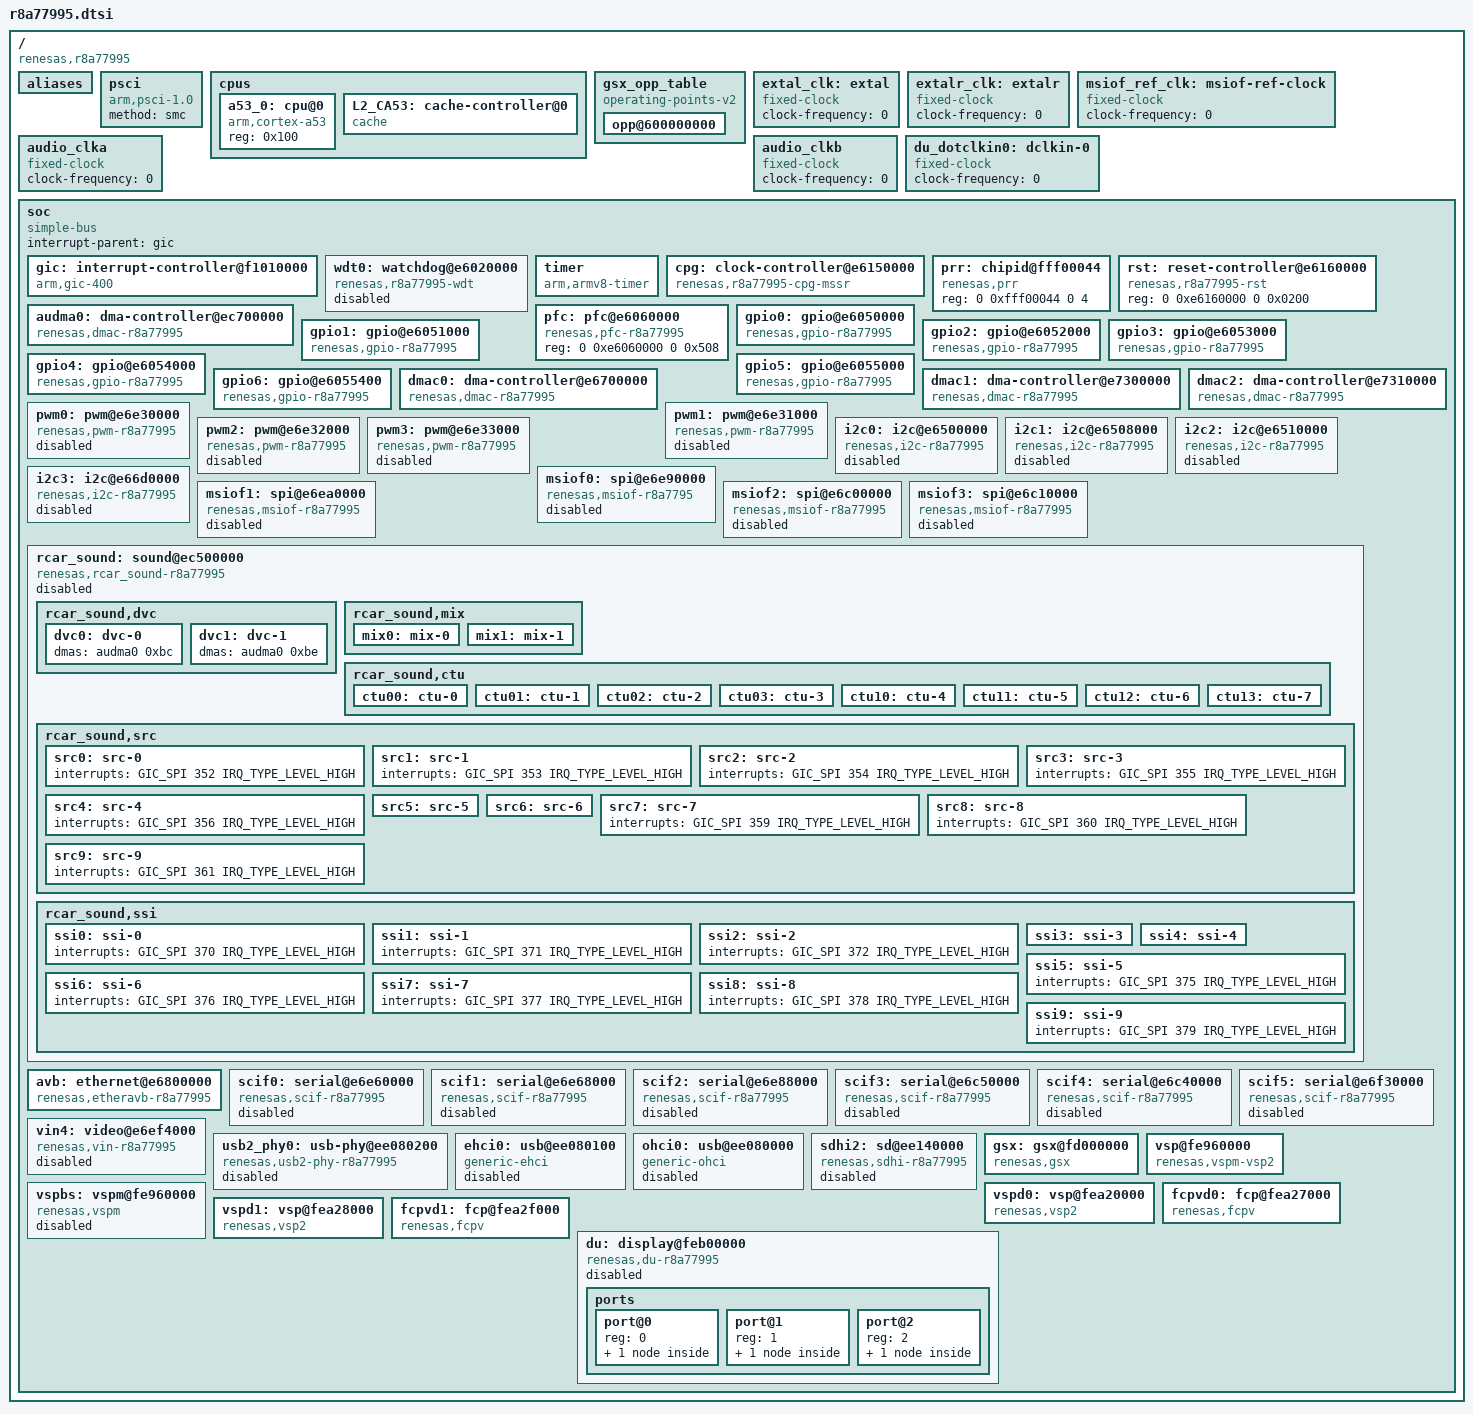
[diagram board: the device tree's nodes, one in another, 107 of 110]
/*
 * Device Tree Source for the r8a77995 SoC
 *
 * Copyright (C) 2017 Renesas Electronics Corp.
 *
 * This file is licensed under the terms of the GNU General Public License
 * version 2.  This program is licensed "as is" without any warranty of any
 * kind, whether express or implied.
 */

#include <dt-bindings/clock/r8a77995-cpg-mssr.h>
#include <dt-bindings/interrupt-controller/arm-gic.h>

/ {
	compatible = "renesas,r8a77995";
	#address-cells = <2>;
	#size-cells = <2>;

	aliases {
		i2c0 = &i2c0;
		i2c1 = &i2c1;
		i2c2 = &i2c2;
		i2c3 = &i2c3;
		spi1 = &msiof0;
		spi2 = &msiof1;
		spi3 = &msiof2;
		spi4 = &msiof3;
		vin4 = &vin4;
	};

	psci {
		compatible = "arm,psci-1.0";
		method = "smc";
	};

	cpus {
		#address-cells = <1>;
		#size-cells = <0>;

		a53_0: cpu@0 {
			compatible = "arm,cortex-a53", "arm,armv8";
			reg = <0x100>;
			device_type = "cpu";
		};

		L2_CA53: cache-controller@0 {
			compatible = "cache";
			reg = <0x100>;
			cache-unified;
			cache-level = <2>;
		};
	};

	gsx_opp_table: gsx_opp_table {
		compatible = "operating-points-v2";

		opp@600000000 {
			opp-hz = /bits/ 64 <600000000>;
			opp-microvolt = <1030000>;
		};
	};

	extal_clk: extal {
		compatible = "fixed-clock";
		#clock-cells = <0>;
		/* This value must be overridden by the board */
		clock-frequency = <0>;
	};

	extalr_clk: extalr {
		compatible = "fixed-clock";
		#clock-cells = <0>;
		/* This value must be overridden by the board */
		clock-frequency = <0>;
	};

	/* MSIOF reference clock - to be overridden by boards that provide it */
	msiof_ref_clk: msiof-ref-clock {
		compatible = "fixed-clock";
		#clock-cells = <0>;
		clock-frequency = <0>;
	};

	/*
	 * The external audio clocks are configured as 0 Hz fixed frequency
	 * clocks by default.
	 * Boards that provide audio clocks should override them.
	 */
	audio_clka: audio_clka {
		compatible = "fixed-clock";
		#clock-cells = <0>;
		clock-frequency = <0>;
	};

	audio_clkb: audio_clkb {
		compatible = "fixed-clock";
		#clock-cells = <0>;
		clock-frequency = <0>;
	};

	/* DU input dot clock - to be overridden by boards that provide it */
	du_dotclkin0: dclkin-0 {
		compatible = "fixed-clock";
		#clock-cells = <0>;
		clock-frequency = <0>;
	};

	soc {
		compatible = "simple-bus";
		interrupt-parent = <&gic>;

		#address-cells = <2>;
		#size-cells = <2>;
		ranges;

		gic: interrupt-controller@f1010000 {
			compatible = "arm,gic-400";
			#interrupt-cells = <3>;
			#address-cells = <0>;
			interrupt-controller;
			reg = <0x0 0xf1010000 0 0x1000>,
			      <0x0 0xf1020000 0 0x20000>,
			      <0x0 0xf1040000 0 0x20000>,
			      <0x0 0xf1060000 0 0x20000>;
			interrupts = <GIC_PPI 9
					(GIC_CPU_MASK_SIMPLE(1) |
					 IRQ_TYPE_LEVEL_HIGH)>;
		};

		wdt0: watchdog@e6020000 {
			compatible = "renesas,r8a77995-wdt",
				     "renesas,rcar-gen3-wdt";
			reg = <0 0xe6020000 0 0x0c>;
			clocks = <&cpg CPG_MOD 402>;
			power-domains = <&cpg>;
			status = "disabled";
		};

		timer {
			compatible = "arm,armv8-timer";
			interrupts = <GIC_PPI 13
					(GIC_CPU_MASK_SIMPLE(1) |
					 IRQ_TYPE_LEVEL_LOW)>,
				     <GIC_PPI 14
					(GIC_CPU_MASK_SIMPLE(1) |
					 IRQ_TYPE_LEVEL_LOW)>,
				     <GIC_PPI 11
					(GIC_CPU_MASK_SIMPLE(1) |
					 IRQ_TYPE_LEVEL_LOW)>,
				     <GIC_PPI 10
					(GIC_CPU_MASK_SIMPLE(1) |
					 IRQ_TYPE_LEVEL_LOW)>;
		};

		cpg: clock-controller@e6150000 {
			compatible = "renesas,r8a77995-cpg-mssr";
			reg = <0 0xe6150000 0 0x1000>;
			clocks = <&extal_clk>, <&extalr_clk>;
			clock-names = "extal", "extalr";
			#clock-cells = <2>;
			#power-domain-cells = <0>;
		};

		prr: chipid@fff00044 {
			compatible = "renesas,prr";
			reg = <0 0xfff00044 0 4>;
		};

		rst: reset-controller@e6160000 {
			compatible = "renesas,r8a77995-rst";
			reg = <0 0xe6160000 0 0x0200>;
		};

		audma0: dma-controller@ec700000 {
			compatible = "renesas,dmac-r8a77995",
				     "renesas,rcar-dmac";
			reg = <0 0xec700000 0 0x10000>;
			interrupts = <GIC_SPI 350 IRQ_TYPE_LEVEL_HIGH
				      GIC_SPI 320 IRQ_TYPE_LEVEL_HIGH
				      GIC_SPI 321 IRQ_TYPE_LEVEL_HIGH
				      GIC_SPI 322 IRQ_TYPE_LEVEL_HIGH
				      GIC_SPI 323 IRQ_TYPE_LEVEL_HIGH
				      GIC_SPI 324 IRQ_TYPE_LEVEL_HIGH
				      GIC_SPI 325 IRQ_TYPE_LEVEL_HIGH
				      GIC_SPI 326 IRQ_TYPE_LEVEL_HIGH
				      GIC_SPI 327 IRQ_TYPE_LEVEL_HIGH
				      GIC_SPI 328 IRQ_TYPE_LEVEL_HIGH
				      GIC_SPI 329 IRQ_TYPE_LEVEL_HIGH
				      GIC_SPI 330 IRQ_TYPE_LEVEL_HIGH
				      GIC_SPI 331 IRQ_TYPE_LEVEL_HIGH
				      GIC_SPI 332 IRQ_TYPE_LEVEL_HIGH
				      GIC_SPI 333 IRQ_TYPE_LEVEL_HIGH
				      GIC_SPI 334 IRQ_TYPE_LEVEL_HIGH
				      GIC_SPI 335 IRQ_TYPE_LEVEL_HIGH>;
			interrupt-names = "error",
					"ch0", "ch1", "ch2", "ch3",
					"ch4", "ch5", "ch6", "ch7",
					"ch8", "ch9", "ch10", "ch11",
					"ch12", "ch13", "ch14", "ch15";
			clocks = <&cpg CPG_MOD 502>;
			clock-names = "fck";
			power-domains = <&cpg>;
			#dma-cells = <1>;
			dma-channels = <16>;
		};

		pfc: pfc@e6060000 {
			compatible = "renesas,pfc-r8a77995";
			reg = <0 0xe6060000 0 0x508>;
		};

		gpio0: gpio@e6050000 {
			compatible = "renesas,gpio-r8a77995",
				     "renesas,gpio-rcar";
			reg = <0 0xe6050000 0 0x50>;
			interrupts = <GIC_SPI 4 IRQ_TYPE_LEVEL_HIGH>;
			#gpio-cells = <2>;
			gpio-controller;
			gpio-ranges = <&pfc 0 0 9>;
			#interrupt-cells = <2>;
			interrupt-controller;
			clocks = <&cpg CPG_MOD 912>;
			power-domains = <&cpg>;
		};

		gpio1: gpio@e6051000 {
			compatible = "renesas,gpio-r8a77995",
				     "renesas,gpio-rcar";
			reg = <0 0xe6051000 0 0x50>;
			interrupts = <GIC_SPI 5 IRQ_TYPE_LEVEL_HIGH>;
			#gpio-cells = <2>;
			gpio-controller;
			gpio-ranges = <&pfc 0 32 32>;
			#interrupt-cells = <2>;
			interrupt-controller;
			clocks = <&cpg CPG_MOD 911>;
			power-domains = <&cpg>;
		};

		gpio2: gpio@e6052000 {
			compatible = "renesas,gpio-r8a77995",
				     "renesas,gpio-rcar";
			reg = <0 0xe6052000 0 0x50>;
			interrupts = <GIC_SPI 6 IRQ_TYPE_LEVEL_HIGH>;
			#gpio-cells = <2>;
			gpio-controller;
			gpio-ranges = <&pfc 0 64 32>;
			#interrupt-cells = <2>;
			interrupt-controller;
			clocks = <&cpg CPG_MOD 910>;
			power-domains = <&cpg>;
		};

		gpio3: gpio@e6053000 {
			compatible = "renesas,gpio-r8a77995",
				     "renesas,gpio-rcar";
			reg = <0 0xe6053000 0 0x50>;
			interrupts = <GIC_SPI 7 IRQ_TYPE_LEVEL_HIGH>;
			#gpio-cells = <2>;
			gpio-controller;
			gpio-ranges = <&pfc 0 96 10>;
			#interrupt-cells = <2>;
			interrupt-controller;
			clocks = <&cpg CPG_MOD 909>;
			power-domains = <&cpg>;
		};

		gpio4: gpio@e6054000 {
			compatible = "renesas,gpio-r8a77995",
				     "renesas,gpio-rcar";
			reg = <0 0xe6054000 0 0x50>;
			interrupts = <GIC_SPI 8 IRQ_TYPE_LEVEL_HIGH>;
			#gpio-cells = <2>;
			gpio-controller;
			gpio-ranges = <&pfc 0 128 32>;
			#interrupt-cells = <2>;
			interrupt-controller;
			clocks = <&cpg CPG_MOD 908>;
			power-domains = <&cpg>;
		};

		gpio5: gpio@e6055000 {
			compatible = "renesas,gpio-r8a77995",
				     "renesas,gpio-rcar";
			reg = <0 0xe6055000 0 0x50>;
			interrupts = <GIC_SPI 9 IRQ_TYPE_LEVEL_HIGH>;
			#gpio-cells = <2>;
			gpio-controller;
			gpio-ranges = <&pfc 0 160 21>;
			#interrupt-cells = <2>;
			interrupt-controller;
			clocks = <&cpg CPG_MOD 907>;
			power-domains = <&cpg>;
		};

		gpio6: gpio@e6055400 {
			compatible = "renesas,gpio-r8a77995",
				     "renesas,gpio-rcar";
			reg = <0 0xe6055400 0 0x50>;
			interrupts = <GIC_SPI 10 IRQ_TYPE_LEVEL_HIGH>;
			#gpio-cells = <2>;
			gpio-controller;
			gpio-ranges = <&pfc 0 192 14>;
			#interrupt-cells = <2>;
			interrupt-controller;
			clocks = <&cpg CPG_MOD 906>;
			power-domains = <&cpg>;
		};

		dmac0: dma-controller@e6700000 {
			compatible = "renesas,dmac-r8a77995",
				     "renesas,rcar-dmac";
			reg = <0 0xe6700000 0 0x10000>;
			interrupts = <GIC_SPI 199 IRQ_TYPE_LEVEL_HIGH
				      GIC_SPI 200 IRQ_TYPE_LEVEL_HIGH
				      GIC_SPI 201 IRQ_TYPE_LEVEL_HIGH
				      GIC_SPI 202 IRQ_TYPE_LEVEL_HIGH
				      GIC_SPI 203 IRQ_TYPE_LEVEL_HIGH
				      GIC_SPI 204 IRQ_TYPE_LEVEL_HIGH
				      GIC_SPI 205 IRQ_TYPE_LEVEL_HIGH
				      GIC_SPI 206 IRQ_TYPE_LEVEL_HIGH
				      GIC_SPI 207 IRQ_TYPE_LEVEL_HIGH>;
			interrupt-names = "error",
					"ch0", "ch1", "ch2", "ch3",
					"ch4", "ch5", "ch6", "ch7";
			clocks = <&cpg CPG_MOD 219>;
			clock-names = "fck";
			power-domains = <&cpg>;
			#dma-cells = <1>;
			dma-channels = <8>;
		};

		dmac1: dma-controller@e7300000 {
			compatible = "renesas,dmac-r8a77995",
				     "renesas,rcar-dmac";
			reg = <0 0xe7300000 0 0x10000>;
			interrupts = <GIC_SPI 220 IRQ_TYPE_LEVEL_HIGH
				      GIC_SPI 216 IRQ_TYPE_LEVEL_HIGH
				      GIC_SPI 217 IRQ_TYPE_LEVEL_HIGH
				      GIC_SPI 218 IRQ_TYPE_LEVEL_HIGH
				      GIC_SPI 219 IRQ_TYPE_LEVEL_HIGH
				      GIC_SPI 308 IRQ_TYPE_LEVEL_HIGH
				      GIC_SPI 309 IRQ_TYPE_LEVEL_HIGH
				      GIC_SPI 310 IRQ_TYPE_LEVEL_HIGH
				      GIC_SPI 311 IRQ_TYPE_LEVEL_HIGH>;
			interrupt-names = "error",
					"ch0", "ch1", "ch2", "ch3",
					"ch4", "ch5", "ch6", "ch7";
			clocks = <&cpg CPG_MOD 218>;
			clock-names = "fck";
			power-domains = <&cpg>;
			#dma-cells = <1>;
			dma-channels = <8>;
		};

		dmac2: dma-controller@e7310000 {
			compatible = "renesas,dmac-r8a77995",
				     "renesas,rcar-dmac";
			reg = <0 0xe7310000 0 0x10000>;
			interrupts = <GIC_SPI 416 IRQ_TYPE_LEVEL_HIGH
				      GIC_SPI 417 IRQ_TYPE_LEVEL_HIGH
				      GIC_SPI 418 IRQ_TYPE_LEVEL_HIGH
				      GIC_SPI 419 IRQ_TYPE_LEVEL_HIGH
				      GIC_SPI 420 IRQ_TYPE_LEVEL_HIGH
				      GIC_SPI 421 IRQ_TYPE_LEVEL_HIGH
				      GIC_SPI 422 IRQ_TYPE_LEVEL_HIGH
				      GIC_SPI 423 IRQ_TYPE_LEVEL_HIGH
				      GIC_SPI 424 IRQ_TYPE_LEVEL_HIGH>;
			interrupt-names = "error",
					"ch0", "ch1", "ch2", "ch3",
					"ch4", "ch5", "ch6", "ch7";
			clocks = <&cpg CPG_MOD 217>;
			clock-names = "fck";
			power-domains = <&cpg>;
			#dma-cells = <1>;
			dma-channels = <8>;
		};

		pwm0: pwm@e6e30000 {
			compatible = "renesas,pwm-r8a77995", "renesas,pwm-rcar";
			reg = <0 0xe6e30000 0 0x10>;
			#pwm-cells = <2>;
			clocks = <&cpg CPG_MOD 523>;
			power-domains = <&cpg>;
			status = "disabled";
		};

		pwm1: pwm@e6e31000 {
			compatible = "renesas,pwm-r8a77995", "renesas,pwm-rcar";
			reg = <0 0xe6e31000 0 0x10>;
			#pwm-cells = <2>;
			clocks = <&cpg CPG_MOD 523>;
			power-domains = <&cpg>;
			status = "disabled";
		};

		pwm2: pwm@e6e32000 {
			compatible = "renesas,pwm-r8a77995", "renesas,pwm-rcar";
			reg = <0 0xe6e32000 0 0x10>;
			#pwm-cells = <2>;
			clocks = <&cpg CPG_MOD 523>;
			power-domains = <&cpg>;
			status = "disabled";
		};

		pwm3: pwm@e6e33000 {
			compatible = "renesas,pwm-r8a77995", "renesas,pwm-rcar";
			reg = <0 0xe6e33000 0 0x10>;
			#pwm-cells = <2>;
			clocks = <&cpg CPG_MOD 523>;
			power-domains = <&cpg>;
			status = "disabled";
		};

		i2c0: i2c@e6500000 {
			#address-cells = <1>;
			#size-cells = <0>;
			compatible = "renesas,i2c-r8a77995";
			reg = <0 0xe6500000 0 0x40>;
			interrupts = <GIC_SPI 287 IRQ_TYPE_LEVEL_HIGH>;
			clocks = <&cpg CPG_MOD 931>;
			power-domains = <&cpg>;
			i2c-scl-internal-delay-ns = <110>;
			status = "disabled";
		};

		i2c1: i2c@e6508000 {
			#address-cells = <1>;
			#size-cells = <0>;
			compatible = "renesas,i2c-r8a77995";
			reg = <0 0xe6508000 0 0x40>;
			interrupts = <GIC_SPI 288 IRQ_TYPE_LEVEL_HIGH>;
			clocks = <&cpg CPG_MOD 930>;
			power-domains = <&cpg>;
			i2c-scl-internal-delay-ns = <6>;
			status = "disabled";
		};

		i2c2: i2c@e6510000 {
			#address-cells = <1>;
			#size-cells = <0>;
			compatible = "renesas,i2c-r8a77995";
			reg = <0 0xe6510000 0 0x40>;
			interrupts = <GIC_SPI 286 IRQ_TYPE_LEVEL_HIGH>;
			clocks = <&cpg CPG_MOD 929>;
			power-domains = <&cpg>;
			i2c-scl-internal-delay-ns = <6>;
			status = "disabled";
		};

		i2c3: i2c@e66d0000 {
			#address-cells = <1>;
			#size-cells = <0>;
			compatible = "renesas,i2c-r8a77995";
			reg = <0 0xe66d0000 0 0x40>;
			interrupts = <GIC_SPI 290 IRQ_TYPE_LEVEL_HIGH>;
			clocks = <&cpg CPG_MOD 928>;
			power-domains = <&cpg>;
			i2c-scl-internal-delay-ns = <110>;
			status = "disabled";
		};

		msiof0: spi@e6e90000 {
			#address-cells = <1>;
			#size-cells = <0>;
			compatible = "renesas,msiof-r8a7795";
			reg = <0 0xe6e90000 0 0x64>;
			interrupts = <GIC_SPI 156 IRQ_TYPE_LEVEL_HIGH>;
			clocks = <&cpg CPG_MOD 211>, <&msiof_ref_clk>;
			clock-names = "msiof_clk", "msiof_ref_clk";
			dmas = <&dmac1 0x41>, <&dmac1 0x40>;
			dma-names = "tx", "rx";
			power-domains = <&cpg>;
			status = "disabled";
		};

		msiof1: spi@e6ea0000 {
			#address-cells = <1>;
			#size-cells = <0>;
			compatible = "renesas,msiof-r8a77995";
			reg = <0 0xe6ea0000 0 0x0064>;
			interrupts = <GIC_SPI 157 IRQ_TYPE_LEVEL_HIGH>;
			clocks = <&cpg CPG_MOD 210>, <&msiof_ref_clk>;
			clock-names = "msiof_clk", "msiof_ref_clk";
			dmas = <&dmac1 0x43>, <&dmac1 0x42>;
			dma-names = "tx", "rx";
			power-domains = <&cpg>;
			status = "disabled";
		};

		msiof2: spi@e6c00000 {
			#address-cells = <1>;
			#size-cells = <0>;
			compatible = "renesas,msiof-r8a77995";
			reg = <0 0xe6c00000 0 0x0064>;
			interrupts = <GIC_SPI 158 IRQ_TYPE_LEVEL_HIGH>;
			clocks = <&cpg CPG_MOD 209>, <&msiof_ref_clk>;
			clock-names = "msiof_clk", "msiof_ref_clk";
			dmas = <&dmac0 0x45>, <&dmac0 0x44>;
			dma-names = "tx", "rx";
			power-domains = <&cpg>;
			status = "disabled";
		};

		msiof3: spi@e6c10000 {
			#address-cells = <1>;
			#size-cells = <0>;
			compatible = "renesas,msiof-r8a77995";
			reg = <0 0xe6c10000 0 0x0064>;
			interrupts = <GIC_SPI 159 IRQ_TYPE_LEVEL_HIGH>;
			clocks = <&cpg CPG_MOD 208>, <&msiof_ref_clk>;
			clock-names = "msiof_clk", "msiof_ref_clk";
			dmas = <&dmac0 0x47>, <&dmac0 0x46>;
			dma-names = "tx", "rx";
			power-domains = <&cpg>;
			status = "disabled";
		};

		rcar_sound: sound@ec500000 {
			/*
			 * #sound-dai-cells is required
			 *
			 * Single DAI : #sound-dai-cells = <0>;	<&rcar_sound>;
			 * Multi  DAI : #sound-dai-cells = <1>;	<&rcar_sound N>;
			 */
			/*
			 * #clock-cells is required for audio_clkout0/1/2/3
			 *
			 * clkout	: #clock-cells = <0>;	<&rcar_sound>;
			 * clkout0/1/2/3: #clock-cells = <1>;	<&rcar_sound N>;
			 */
			compatible =  "renesas,rcar_sound-r8a77995",
				      "renesas,rcar_sound-gen3";
			reg =	<0 0xec500000 0 0x1000>, /* SCU */
				<0 0xec5a0000 0 0x100>,  /* ADG */
				<0 0xec540000 0 0x1000>, /* SSIU */
				<0 0xec541000 0 0x280>,  /* SSI */
				<0 0xec740000 0 0x200>;  /* Audio DMAC PP */
			reg-names = "scu", "adg", "ssiu", "ssi", "audmapp";

			clocks = <&cpg CPG_MOD 1005>,
				 <&cpg CPG_MOD 1006>, <&cpg CPG_MOD 1007>,
				 <&cpg CPG_MOD 1008>, <&cpg CPG_MOD 1009>,
				 <&cpg CPG_MOD 1010>, <&cpg CPG_MOD 1011>,
				 <&cpg CPG_MOD 1012>, <&cpg CPG_MOD 1013>,
				 <&cpg CPG_MOD 1014>, <&cpg CPG_MOD 1015>,
				 <&cpg CPG_MOD 1022>, <&cpg CPG_MOD 1023>,
				 <&cpg CPG_MOD 1024>, <&cpg CPG_MOD 1025>,
				 <&cpg CPG_MOD 1026>, <&cpg CPG_MOD 1027>,
				 <&cpg CPG_MOD 1028>, <&cpg CPG_MOD 1029>,
				 <&cpg CPG_MOD 1030>, <&cpg CPG_MOD 1031>,
				 <&cpg CPG_MOD 1020>, <&cpg CPG_MOD 1021>,
				 <&cpg CPG_MOD 1020>, <&cpg CPG_MOD 1021>,
				 <&cpg CPG_MOD 1019>, <&cpg CPG_MOD 1018>,
				 <&audio_clka>, <&audio_clkb>,
				 <&cpg CPG_CORE R8A77995_CLK_ZA2>;

			clock-names = "ssi-all",
				      "ssi.9", "ssi.8", "ssi.7", "ssi.6",
				      "ssi.5", "ssi.4", "ssi.3", "ssi.2",
				      "ssi.1", "ssi.0",
				      "src.9", "src.8", "src.7", "src.6",
				      "src.5", "src.4", "src.3", "src.2",
				      "src.1", "src.0",
				      "mix.1", "mix.0",
				      "ctu.1", "ctu.0",
				      "dvc.0", "dvc.1",
				      "clk_a", "clk_b";
			power-domains = <&cpg>;
			status = "disabled";

			rcar_sound,dvc {
				dvc0: dvc-0 {
					dmas = <&audma0 0xbc>;
					dma-names = "tx";
				};
				dvc1: dvc-1 {
					dmas = <&audma0 0xbe>;
					dma-names = "tx";
				};
			};

			rcar_sound,mix {
				mix0: mix-0 { };
				mix1: mix-1 { };
			};

			rcar_sound,ctu {
				ctu00: ctu-0 { };
				ctu01: ctu-1 { };
				ctu02: ctu-2 { };
				ctu03: ctu-3 { };
				ctu10: ctu-4 { };
				ctu11: ctu-5 { };
				ctu12: ctu-6 { };
				ctu13: ctu-7 { };
			};

			rcar_sound,src {
				src0: src-0 {
					interrupts =
					    <GIC_SPI 352 IRQ_TYPE_LEVEL_HIGH>;
				};
				src1: src-1 {
					interrupts =
					    <GIC_SPI 353 IRQ_TYPE_LEVEL_HIGH>;
				};
				src2: src-2 {
					interrupts =
					    <GIC_SPI 354 IRQ_TYPE_LEVEL_HIGH>;
				};
				src3: src-3 {
					interrupts =
					    <GIC_SPI 355 IRQ_TYPE_LEVEL_HIGH>;
				};
				src4: src-4 {
					interrupts =
					    <GIC_SPI 356 IRQ_TYPE_LEVEL_HIGH>;
				};
				src5: src-5 {
					interrupts =
					    <GIC_SPI 357 IRQ_TYPE_LEVEL_HIGH>;
					dmas = <&audma0 0x8f>, <&audma0 0xb2>;
					dma-names = "rx", "tx";
				};
				src6: src-6 {
					interrupts =
					    <GIC_SPI 358 IRQ_TYPE_LEVEL_HIGH>;
					dmas = <&audma0 0x91>, <&audma0 0xb4>;
					dma-names = "rx", "tx";
				};
				src7: src-7 {
					interrupts =
					    <GIC_SPI 359 IRQ_TYPE_LEVEL_HIGH>;
				};
				src8: src-8 {
					interrupts =
					    <GIC_SPI 360 IRQ_TYPE_LEVEL_HIGH>;
				};
				src9: src-9 {
					interrupts =
					    <GIC_SPI 361 IRQ_TYPE_LEVEL_HIGH>;
				};
			};

			rcar_sound,ssi {
				ssi0: ssi-0 {
					interrupts =
					    <GIC_SPI 370 IRQ_TYPE_LEVEL_HIGH>;
				};
				ssi1: ssi-1 {
					 interrupts =
					     <GIC_SPI 371 IRQ_TYPE_LEVEL_HIGH>;
				};
				ssi2: ssi-2 {
					interrupts =
					    <GIC_SPI 372 IRQ_TYPE_LEVEL_HIGH>;
				};
				ssi3: ssi-3 {
					interrupts =
					    <GIC_SPI 373 IRQ_TYPE_LEVEL_HIGH>;
					dmas = <&audma0 0x07>, <&audma0 0x08>,
					       <&audma0 0x6f>, <&audma0 0x70>;
					dma-names = "rx", "tx", "rxu", "txu";
				};
				ssi4: ssi-4 {
					interrupts =
					    <GIC_SPI 374 IRQ_TYPE_LEVEL_HIGH>;
					dmas = <&audma0 0x09>, <&audma0 0x0a>,
					       <&audma0 0x71>, <&audma0 0x72>;
					dma-names = "rx", "tx", "rxu", "txu";
				};
				ssi5: ssi-5 {
					interrupts =
					    <GIC_SPI 375 IRQ_TYPE_LEVEL_HIGH>;
				};
				ssi6: ssi-6 {
					interrupts =
					    <GIC_SPI 376 IRQ_TYPE_LEVEL_HIGH>;
				};
				ssi7: ssi-7 {
					interrupts =
					    <GIC_SPI 377 IRQ_TYPE_LEVEL_HIGH>;
				};
				ssi8: ssi-8 {
					interrupts =
					    <GIC_SPI 378 IRQ_TYPE_LEVEL_HIGH>;
				};
				ssi9: ssi-9 {
					interrupts =
					    <GIC_SPI 379 IRQ_TYPE_LEVEL_HIGH>;
				};
			};
		};

		avb: ethernet@e6800000 {
			compatible = "renesas,etheravb-r8a77995",
				     "renesas,etheravb-rcar-gen3";
			reg = <0 0xe6800000 0 0x800>, <0 0xe6a00000 0 0x10000>;
			interrupts = <GIC_SPI 39 IRQ_TYPE_LEVEL_HIGH>,
				     <GIC_SPI 40 IRQ_TYPE_LEVEL_HIGH>,
				     <GIC_SPI 41 IRQ_TYPE_LEVEL_HIGH>,
				     <GIC_SPI 42 IRQ_TYPE_LEVEL_HIGH>,
				     <GIC_SPI 43 IRQ_TYPE_LEVEL_HIGH>,
				     <GIC_SPI 44 IRQ_TYPE_LEVEL_HIGH>,
				     <GIC_SPI 45 IRQ_TYPE_LEVEL_HIGH>,
				     <GIC_SPI 46 IRQ_TYPE_LEVEL_HIGH>,
				     <GIC_SPI 47 IRQ_TYPE_LEVEL_HIGH>,
				     <GIC_SPI 48 IRQ_TYPE_LEVEL_HIGH>,
				     <GIC_SPI 49 IRQ_TYPE_LEVEL_HIGH>,
				     <GIC_SPI 50 IRQ_TYPE_LEVEL_HIGH>,
				     <GIC_SPI 51 IRQ_TYPE_LEVEL_HIGH>,
				     <GIC_SPI 52 IRQ_TYPE_LEVEL_HIGH>,
				     <GIC_SPI 53 IRQ_TYPE_LEVEL_HIGH>,
				     <GIC_SPI 54 IRQ_TYPE_LEVEL_HIGH>,
				     <GIC_SPI 55 IRQ_TYPE_LEVEL_HIGH>,
				     <GIC_SPI 56 IRQ_TYPE_LEVEL_HIGH>,
				     <GIC_SPI 57 IRQ_TYPE_LEVEL_HIGH>,
				     <GIC_SPI 58 IRQ_TYPE_LEVEL_HIGH>,
				     <GIC_SPI 59 IRQ_TYPE_LEVEL_HIGH>,
				     <GIC_SPI 60 IRQ_TYPE_LEVEL_HIGH>,
				     <GIC_SPI 61 IRQ_TYPE_LEVEL_HIGH>,
				     <GIC_SPI 62 IRQ_TYPE_LEVEL_HIGH>,
				     <GIC_SPI 63 IRQ_TYPE_LEVEL_HIGH>;
			interrupt-names = "ch0", "ch1", "ch2", "ch3",
					  "ch4", "ch5", "ch6", "ch7",
					  "ch8", "ch9", "ch10", "ch11",
					  "ch12", "ch13", "ch14", "ch15",
					  "ch16", "ch17", "ch18", "ch19",
					  "ch20", "ch21", "ch22", "ch23",
					  "ch24";
			clocks = <&cpg CPG_MOD 812>;
			power-domains = <&cpg>;
			phy-mode = "rgmii-txid";
			#address-cells = <1>;
			#size-cells = <0>;
		};

		scif0: serial@e6e60000 {
			compatible = "renesas,scif-r8a77995",
				     "renesas,rcar-gen3-scif", "renesas,scif";
			reg = <0 0xe6e60000 0 64>;
			interrupts = <GIC_SPI 152 IRQ_TYPE_LEVEL_HIGH>;
			clocks = <&cpg CPG_MOD 207>;
			clock-names = "fck";
			power-domains = <&cpg>;
			status = "disabled";
		};

		scif1: serial@e6e68000 {
			compatible = "renesas,scif-r8a77995",
				     "renesas,rcar-gen3-scif", "renesas,scif";
			reg = <0 0xe6e68000 0 64>;
			interrupts = <GIC_SPI 153 IRQ_TYPE_LEVEL_HIGH>;
			clocks = <&cpg CPG_MOD 206>;
			clock-names = "fck";
			power-domains = <&cpg>;
			status = "disabled";
		};

		scif2: serial@e6e88000 {
			compatible = "renesas,scif-r8a77995",
				     "renesas,rcar-gen3-scif", "renesas,scif";
			reg = <0 0xe6e88000 0 64>;
			interrupts = <GIC_SPI 164 IRQ_TYPE_LEVEL_HIGH>;
			clocks = <&cpg CPG_MOD 310>;
			clock-names = "fck";
			power-domains = <&cpg>;
			status = "disabled";
		};

		scif3: serial@e6c50000 {
			compatible = "renesas,scif-r8a77995",
				     "renesas,rcar-gen3-scif", "renesas,scif";
			reg = <0 0xe6c50000 0 64>;
			interrupts = <GIC_SPI 23 IRQ_TYPE_LEVEL_HIGH>;
			clocks = <&cpg CPG_MOD 204>;
			clock-names = "fck";
			power-domains = <&cpg>;
			status = "disabled";
		};

		scif4: serial@e6c40000 {
			compatible = "renesas,scif-r8a77995",
				     "renesas,rcar-gen3-scif", "renesas,scif";
			reg = <0 0xe6c40000 0 64>;
			interrupts = <GIC_SPI 16 IRQ_TYPE_LEVEL_HIGH>;
			clocks = <&cpg CPG_MOD 203>;
			clock-names = "fck";
			power-domains = <&cpg>;
			status = "disabled";
		};

		scif5: serial@e6f30000 {
			compatible = "renesas,scif-r8a77995",
				     "renesas,rcar-gen3-scif", "renesas,scif";
			reg = <0 0xe6f30000 0 64>;
			interrupts = <GIC_SPI 17 IRQ_TYPE_LEVEL_HIGH>;
			clocks = <&cpg CPG_MOD 202>;
			clock-names = "fck";
			power-domains = <&cpg>;
			status = "disabled";
		};

		vin4: video@e6ef4000 {
			compatible = "renesas,vin-r8a77995";
			reg = <0 0xe6ef4000 0 0x1000>;
			interrupts = <GIC_SPI 174 IRQ_TYPE_LEVEL_HIGH>;
			clocks = <&cpg CPG_MOD 807>;
			power-domains = <&cpg>;
			status = "disabled";
		};

		usb2_phy0: usb-phy@ee080200 {
			compatible = "renesas,usb2-phy-r8a77995";
			reg = <0 0xee080200 0 0x700>;
			interrupts = <GIC_SPI 108 IRQ_TYPE_LEVEL_HIGH>;
			clocks = <&cpg CPG_MOD 703>;
			power-domains = <&cpg>;
			#phy-cells = <0>;
			status = "disabled";
		};

		ehci0: usb@ee080100 {
			compatible = "generic-ehci";
			reg = <0 0xee080100 0 0x100>;
			interrupts = <GIC_SPI 108 IRQ_TYPE_LEVEL_HIGH>;
			clocks = <&cpg CPG_MOD 703>;
			phys = <&usb2_phy0>;
			phy-names = "usb";
			power-domains = <&cpg>;
			status = "disabled";
		};

		ohci0: usb@ee080000 {
			compatible = "generic-ohci";
			reg = <0 0xee080000 0 0x100>;
			interrupts = <GIC_SPI 108 IRQ_TYPE_LEVEL_HIGH>;
			clocks = <&cpg CPG_MOD 703>;
			phys = <&usb2_phy0>;
			phy-names = "usb";
			power-domains = <&cpg>;
			status = "disabled";
		};

		sdhi2: sd@ee140000 {
			compatible = "renesas,sdhi-r8a77995";
			reg = <0 0xee140000 0 0x2000>;
			interrupts = <GIC_SPI 167 IRQ_TYPE_LEVEL_HIGH>;
			clocks = <&cpg CPG_MOD 312>;
			max-frequency = <200000000>;
			power-domains = <&cpg>;
			status = "disabled";
		};

		gsx: gsx@fd000000 {
			compatible = "renesas,gsx";
			reg = <0 0xfd000000 0 0x3ffff>;
			interrupts = <GIC_SPI 119 IRQ_TYPE_LEVEL_HIGH>;
			clocks = <&cpg CPG_MOD 112>;
			operating-points-v2 = <&gsx_opp_table>;
			power-domains = <&cpg>;
		};

		vsp@fe960000 {
			compatible = "renesas,vspm-vsp2";
			reg = <0 0xfe960000 0 0x8000>;
			renesas,has-brs;
			renesas,#rpf = <2>;
			renesas,#uds = <0>;
			renesas,#wpf = <1>;
		};

		vspbs: vspm@fe960000 {
			compatible = "renesas,vspm";
			reg = <0 0xfe960000 0 0x8000>, <0 0xfe96f000 0 0x200>;
			interrupts = <GIC_SPI 465 IRQ_TYPE_LEVEL_HIGH>;
			clocks = <&cpg CPG_MOD 627>, <&cpg CPG_MOD 607>;
			clock-names = "vsp", "fcp";
			renesas,#ch = <3>;
			renesas,#rpf = <3>;
			renesas,#rpf_clut = <3>;
			renesas,#wpf_rot = <0>;
			renesas,has-brs;
			renesas,#read_outstanding = <0>;
			renesas,#start_reservation = <2>;
			power-domains = <&cpg>;
			status = "disabled";
		};

		vspd0: vsp@fea20000 {
			compatible = "renesas,vsp2";
			reg = <0 0xfea20000 0 0x4000>;
			interrupts = <GIC_SPI 466 IRQ_TYPE_LEVEL_HIGH>;
			clocks = <&cpg CPG_MOD 623>;
			power-domains = <&cpg>;

			renesas,fcp = <&fcpvd0>;
		};

		fcpvd0: fcp@fea27000 {
			compatible = "renesas,fcpv";
			reg = <0 0xfea27000 0 0x200>;
			clocks = <&cpg CPG_MOD 603>;
			power-domains = <&cpg>;
		};

		vspd1: vsp@fea28000 {
			compatible = "renesas,vsp2";
			reg = <0 0xfea28000 0 0x4000>;
			interrupts = <GIC_SPI 467 IRQ_TYPE_LEVEL_HIGH>;
			clocks = <&cpg CPG_MOD 622>;
			power-domains = <&cpg>;

			renesas,fcp = <&fcpvd1>;
		};

		fcpvd1: fcp@fea2f000 {
			compatible = "renesas,fcpv";
			reg = <0 0xfea2f000 0 0x200>;
			clocks = <&cpg CPG_MOD 602>;
			power-domains = <&cpg>;
		};

		du: display@feb00000 {
			compatible = "renesas,du-r8a77995";
			reg = <0 0xfeb00000 0 0x40000>,
			      <0 0xfeb90000 0 0x100>,
			      <0 0xfeb90100 0 0x100>;
			reg-names = "du", "lvds.0", "lvds.1";
			interrupts = <GIC_SPI 256 IRQ_TYPE_LEVEL_HIGH>,
				     <GIC_SPI 268 IRQ_TYPE_LEVEL_HIGH>;
			clocks = <&cpg CPG_MOD 724>,
				 <&cpg CPG_MOD 723>,
				 <&cpg CPG_MOD 727>,
				 <&cpg CPG_MOD 727>,
				 <&du_dotclkin0>;
			clock-names = "du.0", "du.1", "lvds.0","lvds.1",
				      "dclkin.0";
			status = "disabled";

			vsps = <&vspd0 &vspd1>;

			ports {
				#address-cells = <1>;
				#size-cells = <0>;

				port@0 {
					reg = <0>;
					du_out_rgb: endpoint {
					};
				};
				port@1 {
					reg = <1>;
					du_out_lvds0: endpoint {
					};
				};
				port@2 {
					reg = <2>;
					du_out_lvds1: endpoint {
					};
				};
			};
		};
	};
};
